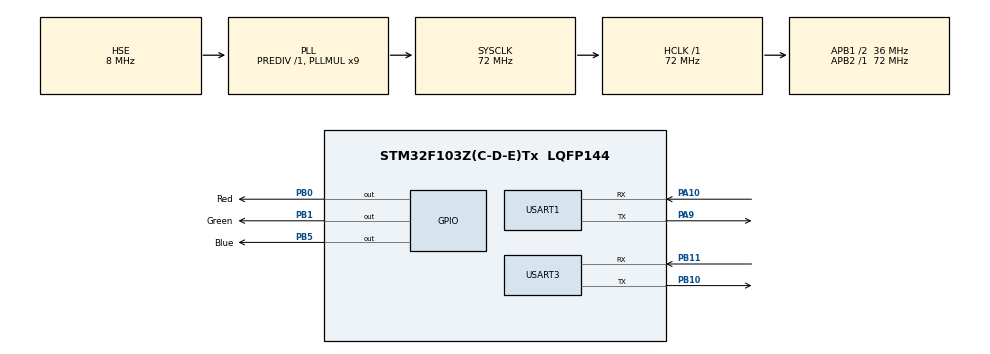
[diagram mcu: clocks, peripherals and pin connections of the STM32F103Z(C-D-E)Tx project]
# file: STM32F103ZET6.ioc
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FREERTOS.Tasks01=defaultTask,24,128,StartDefaultTask,Default,NULL,Dynamic,NULL,NULL
Mcu.Family=STM32F1
Mcu.Name=STM32F103Z(C-D-E)Tx
Mcu.Package=LQFP144
NVIC.PriorityGroup=NVIC_PRIORITYGROUP_4
NVIC.TIM8_UP_IRQn=true\:15\:0\:false\:false\:true\:false\:false\:true\:true
NVIC.TimeBase=TIM8_UP_IRQn
NVIC.TimeBaseIP=TIM8
OSC_IN.Mode=HSE-External-Oscillator
OSC_IN.Signal=RCC_OSC_IN
OSC_OUT.Mode=HSE-External-Oscillator
OSC_OUT.Signal=RCC_OSC_OUT
PA10.Mode=Asynchronous
PA10.Signal=USART1_RX
PA13.Mode=Serial_Wire
PA13.Signal=SYS_JTMS-SWDIO
PA14.Mode=Serial_Wire
PA14.Signal=SYS_JTCK-SWCLK
PA9.Mode=Asynchronous
PA9.Signal=USART1_TX
PB0.GPIO_Label=Red
PB0.Signal=GPIO_Output
PB1.GPIO_Label=Green
PB1.Signal=GPIO_Output
PB10.Mode=Asynchronous
PB10.Signal=USART3_TX
PB11.Mode=Asynchronous
PB11.Signal=USART3_RX
PB5.GPIO_Label=Blue
PB5.Signal=GPIO_Output
PC14-OSC32_IN.Mode=LSE-External-Oscillator
PC14-OSC32_IN.Signal=RCC_OSC32_IN
PC15-OSC32_OUT.Mode=LSE-External-Oscillator
PC15-OSC32_OUT.Signal=RCC_OSC32_OUT
ProjectManager.HeapSize=0x200
ProjectManager.StackSize=0x400
ProjectManager.TargetToolchain=Makefile
RCC.AHBFreq_Value=72000000
RCC.APB1CLKDivider=RCC_HCLK_DIV2
RCC.APB1Freq_Value=36000000
RCC.APB1TimFreq_Value=72000000
RCC.APB2Freq_Value=72000000
RCC.APB2TimFreq_Value=72000000
RCC.HCLKFreq_Value=72000000
RCC.PLLMUL=RCC_PLL_MUL9
RCC.PLLSourceVirtual=RCC_PLLSOURCE_HSE
RCC.SYSCLKFreq_VALUE=72000000
RCC.SYSCLKSource=RCC_SYSCLKSOURCE_PLLCLK
RCC.USBFreq_Value=72000000
USART1.VirtualMode=VM_ASYNC
USART3.VirtualMode=VM_ASYNC
VP_FREERTOS_VS_CMSIS_V2.Mode=CMSIS_V2
VP_SYS_VS_tim8.Mode=TIM8
board=custom

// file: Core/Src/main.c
/* USER CODE BEGIN Header */
/**
 ******************************************************************************
 * @file           : main.c
 * @brief          : Main program body
 ******************************************************************************
 * @attention
 *
 * Copyright (c) 2023 STMicroelectronics.
 * All rights reserved.
 *
 * This software is licensed under terms that can be found in the LICENSE file
 * in the root directory of this software component.
 * If no LICENSE file comes with this software, it is provided AS-IS.
 *
 ******************************************************************************
 */
/* USER CODE END Header */
#include "main.h"
#include "cmsis_os.h"
#include "gpio.h"
#include "usart.h"

/* USER CODE BEGIN Includes */
#include "FreeRTOS.h"
#include <stdio.h>
/* USER CODE END Includes */

void SystemClock_Config(void);
void MX_FREERTOS_Init(void);

int main(void)
{

	/* MCU Configuration--------------------------------------------------------*/

	/* Reset of all peripherals, Initializes the Flash interface and the Systick. */
	HAL_Init();

	/* Configure the system clock */
	SystemClock_Config();

	/* Initialize all configured peripherals */
	MX_GPIO_Init();
	MX_USART1_UART_Init();
	MX_USART3_UART_Init();

	/* Init scheduler */
	osKernelInitialize();

	/* Call init function for freertos objects (in freertos.c) */
	MX_FREERTOS_Init();

	/* Start scheduler */
	osKernelStart();

	/* We should never get here as control is now taken by the scheduler */
	/* Infinite loop */
	/* USER CODE BEGIN WHILE */
	// USART3_Write("AT\r\n", 4);
	while (1) {
		/* USER CODE END WHILE */
		// printf("hello\r\n");
		/* USER CODE BEGIN 3 */
		// HAL_GPIO_TogglePin(LEDB_PORT, LEDB_PIN);
		// HAL_Delay(1000);
	}
	/* USER CODE END 3 */
}

void SystemClock_Config(void)
{
	RCC_OscInitTypeDef RCC_OscInitStruct = {0};
	RCC_ClkInitTypeDef RCC_ClkInitStruct = {0};

	/** Initializes the RCC Oscillators according to the specified parameters
	 * in the RCC_OscInitTypeDef structure.
	 */
	RCC_OscInitStruct.OscillatorType = RCC_OSCILLATORTYPE_HSE;
	RCC_OscInitStruct.HSEState = RCC_HSE_ON;
	RCC_OscInitStruct.HSEPredivValue = RCC_HSE_PREDIV_DIV1;
	RCC_OscInitStruct.HSIState = RCC_HSI_ON;
	RCC_OscInitStruct.PLL.PLLState = RCC_PLL_ON;
	RCC_OscInitStruct.PLL.PLLSource = RCC_PLLSOURCE_HSE;
	RCC_OscInitStruct.PLL.PLLMUL = RCC_PLL_MUL9;
	if (HAL_RCC_OscConfig(&RCC_OscInitStruct) != HAL_OK) {
		Error_Handler();
	}

	/** Initializes the CPU, AHB and APB buses clocks
	 */
	RCC_ClkInitStruct.ClockType = RCC_CLOCKTYPE_HCLK | RCC_CLOCKTYPE_SYSCLK |
				      RCC_CLOCKTYPE_PCLK1 | RCC_CLOCKTYPE_PCLK2;
	RCC_ClkInitStruct.SYSCLKSource = RCC_SYSCLKSOURCE_PLLCLK;
	RCC_ClkInitStruct.AHBCLKDivider = RCC_SYSCLK_DIV1;
	RCC_ClkInitStruct.APB1CLKDivider = RCC_HCLK_DIV2;
	RCC_ClkInitStruct.APB2CLKDivider = RCC_HCLK_DIV1;

	if (HAL_RCC_ClockConfig(&RCC_ClkInitStruct, FLASH_LATENCY_2) != HAL_OK) {
		Error_Handler();
	}
}

void HAL_TIM_PeriodElapsedCallback(TIM_HandleTypeDef *htim)
{
	if (htim->Instance == TIM8) {
		HAL_IncTick();
	}
}

void Error_Handler(void)
{
	__disable_irq();
	while (1) {
	}
}

#ifdef USE_FULL_ASSERT
/**
 * @brief  Reports the name of the source file and the source line number
 *         where the assert_param error has occurred.
 * @param  file: pointer to the source file name
 * @param  line: assert_param error line source number
 * @retval None
 */
void assert_failed(uint8_t *file, uint32_t line)
{
	/* USER CODE BEGIN 6 */
	/* User can add his own implementation to report the file name and line
	   number, ex: printf("Wrong parameters value: file %s on line %d\r\n", file,
	   line) */
	/* USER CODE END 6 */
}
#endif /* USE_FULL_ASSERT */

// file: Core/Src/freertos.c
/* USER CODE BEGIN Header */
/**
 ******************************************************************************
 * File Name          : freertos.c
 * Description        : Code for freertos applications
 ******************************************************************************
 * @attention
 *
 * Copyright (c) 2023 STMicroelectronics.
 * All rights reserved.
 *
 * This software is licensed under terms that can be found in the LICENSE file
 * in the root directory of this software component.
 * If no LICENSE file comes with this software, it is provided AS-IS.
 *
 ******************************************************************************
 */
/* USER CODE END Header */

#include "FreeRTOS.h"
#include "cmsis_os.h"
#include "main.h"
#include "task.h"

/* Definitions for defaultTask */
osThreadId_t defaultTaskHandle;
osThreadId_t taskParser;
osThreadId_t task_at_connect;

const osThreadAttr_t taskParser_attributes = {
	.name = "taskParser",
	.stack_size = 128 * 4,
	.priority = (osPriority_t)osPriorityNormal1,
};

const osThreadAttr_t defaultTask_attributes = {
	.name = "defaultTask",
	.stack_size = 128 * 4,
	.priority = (osPriority_t)osPriorityNormal,
};

const osThreadAttr_t at_connect_attributes = {
	.name = "at_connect",
	.stack_size = 128 * 4,
	.priority = (osPriority_t)osPriorityNormal2,
};

/* USER CODE BEGIN FunctionPrototypes */
void task_parser(void *argument);
void at_connect(void *argument);
/* USER CODE END FunctionPrototypes */

void StartDefaultTask(void *argument);

void MX_FREERTOS_Init(void); /* (MISRA C 2004 rule 8.1) */

void MX_FREERTOS_Init(void)
{

	/* Create the thread(s) */
	/* creation of defaultTask */
	defaultTaskHandle = osThreadNew(StartDefaultTask, NULL, &defaultTask_attributes);
	taskParser = osThreadNew(task_parser, NULL, &taskParser_attributes);
	task_at_connect = osThreadNew(at_connect, NULL, &at_connect_attributes);

}

void StartDefaultTask(void *argument)
{
	for (;;) {
		osDelay(1);
	}
}

/* USER CODE BEGIN Application */
void task_parser(void *argument)
{
	for (;;) {
		osDelay(1);
	}
}
void at_connect(void *argument)
{
	for (;;) {
		osDelay(1);
	}
}
/* USER CODE END Application */
